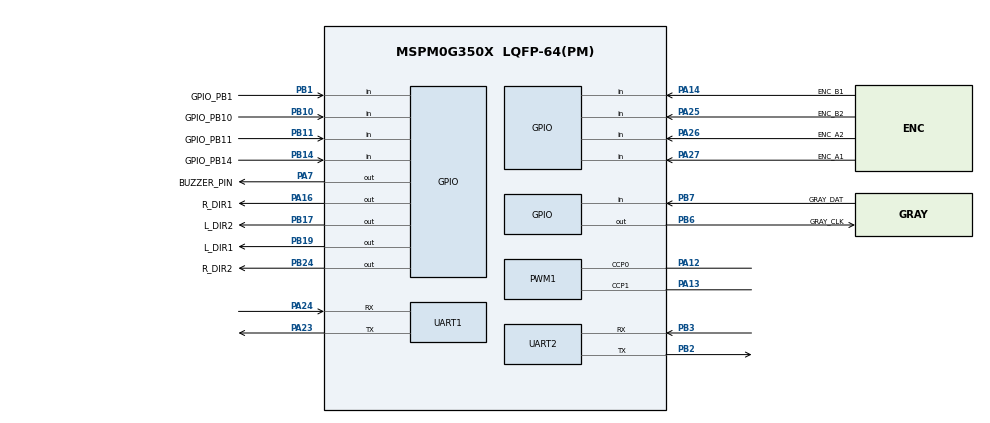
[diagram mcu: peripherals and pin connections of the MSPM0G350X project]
/**
 *
 * @cliArgs --device "MSPM0G350X" --part "Default" --package "LQFP-64(PM)" --product "mspm0_sdk@2.10.00.04"
 * @versions {"tool":"1.28.0+4696"}
 */

/**
 * Import the modules used in this configuration.
 */
const ADC12  = scripting.addModule("/ti/driverlib/ADC12", {}, false);
const ADC121 = ADC12.addInstance();
const GPIO   = scripting.addModule("/ti/driverlib/GPIO", {}, false);
const GPIO1  = GPIO.addInstance();
const GPIO2  = GPIO.addInstance();
const GPIO3  = GPIO.addInstance();
const GPIO4  = GPIO.addInstance();
const GPIO5  = GPIO.addInstance();
const GPIO6  = GPIO.addInstance();
const PWM    = scripting.addModule("/ti/driverlib/PWM", {}, false);
const PWM1   = PWM.addInstance();
const SYSCTL = scripting.addModule("/ti/driverlib/SYSCTL");
const TIMER  = scripting.addModule("/ti/driverlib/TIMER", {}, false);
const TIMER1 = TIMER.addInstance();
const UART   = scripting.addModule("/ti/driverlib/UART", {}, false);
const UART1  = UART.addInstance();
const UART2  = UART.addInstance();
const UART3  = UART.addInstance();

/**
 * Write custom configuration values to the imported modules.
 */
ADC121.$name                             = "ir_sensor";
ADC121.repeatMode                        = true;
ADC121.peripheral.adcPin0.$assign        = "PA15";
ADC121.adcPin0Config.hideOutputInversion = scripting.forceWrite(false);
ADC121.adcPin0Config.$name               = "ti_driverlib_gpio_GPIOPinGeneric8";

const Board = scripting.addModule("/ti/driverlib/Board", {}, false);

GPIO1.$name                         = "GRAY_SENSOR";
GPIO1.associatedPins.create(2);
GPIO1.associatedPins[0].$name       = "GRAY_CLK";
GPIO1.associatedPins[0].pin.$assign = "PB6";
GPIO1.associatedPins[1].$name       = "GRAY_DAT";
GPIO1.associatedPins[1].direction   = "INPUT";
GPIO1.associatedPins[1].pin.$assign = "PB7";

GPIO2.$name                         = "MOTOR_DIR";
GPIO2.associatedPins.create(4);
GPIO2.associatedPins[0].$name       = "L_DIR1";
GPIO2.associatedPins[0].pin.$assign = "PB19";
GPIO2.associatedPins[1].$name       = "L_DIR2";
GPIO2.associatedPins[1].pin.$assign = "PB17";
GPIO2.associatedPins[2].$name       = "R_DIR1";
GPIO2.associatedPins[2].pin.$assign = "PA16";
GPIO2.associatedPins[3].$name       = "R_DIR2";
GPIO2.associatedPins[3].pin.$assign = "PB24";

GPIO3.$name                         = "BUZZER";
GPIO3.associatedPins[0].$name       = "BUZZER_PIN";
GPIO3.associatedPins[0].pin.$assign = "PA7";

GPIO4.$name                         = "EXIT_ANJIAN";
GPIO4.associatedPins.create(4);
GPIO4.associatedPins[0].$name       = "GPIO_PB1";
GPIO4.associatedPins[0].direction   = "INPUT";
GPIO4.associatedPins[0].pin.$assign = "PB1";
GPIO4.associatedPins[1].$name       = "GPIO_PB10";
GPIO4.associatedPins[1].direction   = "INPUT";
GPIO4.associatedPins[1].pin.$assign = "PB10";
GPIO4.associatedPins[2].$name       = "GPIO_PB11";
GPIO4.associatedPins[2].direction   = "INPUT";
GPIO4.associatedPins[2].pin.$assign = "PB11";
GPIO4.associatedPins[3].$name       = "GPIO_PB14";
GPIO4.associatedPins[3].direction   = "INPUT";
GPIO4.associatedPins[3].pin.$assign = "PB14";

GPIO5.$name                         = "ENCODER";
GPIO5.associatedPins.create(4);
GPIO5.associatedPins[0].$name       = "ENC_A1";
GPIO5.associatedPins[0].direction   = "INPUT";
GPIO5.associatedPins[0].interruptEn = true;
GPIO5.associatedPins[0].polarity    = "RISE";
GPIO5.associatedPins[0].pin.$assign = "PA27";
GPIO5.associatedPins[1].$name       = "ENC_A2";
GPIO5.associatedPins[1].direction   = "INPUT";
GPIO5.associatedPins[1].interruptEn = true;
GPIO5.associatedPins[1].polarity    = "RISE";
GPIO5.associatedPins[1].pin.$assign = "PA26";
GPIO5.associatedPins[2].$name       = "ENC_B1";
GPIO5.associatedPins[2].direction   = "INPUT";
GPIO5.associatedPins[2].interruptEn = true;
GPIO5.associatedPins[2].polarity    = "RISE";
GPIO5.associatedPins[2].pin.$assign = "PA14";
GPIO5.associatedPins[3].$name       = "ENC_B2";
GPIO5.associatedPins[3].direction   = "INPUT";
GPIO5.associatedPins[3].interruptEn = true;
GPIO5.associatedPins[3].polarity    = "RISE";
GPIO5.associatedPins[3].pin.$assign = "PA25";

GPIO6.$name                   = "GPIO_GRP_0";
GPIO6.associatedPins[0].$name = "PIN_0";

PWM1.$name                              = "PWM_MOTOR";
PWM1.timerStartTimer                    = true;
PWM1.timerCount                         = 4000;
PWM1.pwmMode                            = "EDGE_ALIGN_UP";
PWM1.peripheral.$assign                 = "TIMG0";
PWM1.peripheral.ccp0Pin.$assign         = "PA12";
PWM1.peripheral.ccp1Pin.$assign         = "PA13";
PWM1.PWM_CHANNEL_0.$name                = "ti_driverlib_pwm_PWMTimerCC0";
PWM1.PWM_CHANNEL_0.ccValue              = 2000;
PWM1.PWM_CHANNEL_1.$name                = "ti_driverlib_pwm_PWMTimerCC1";
PWM1.PWM_CHANNEL_1.ccValue              = 2000;
PWM1.ccp0PinConfig.direction            = scripting.forceWrite("OUTPUT");
PWM1.ccp0PinConfig.hideOutputInversion  = scripting.forceWrite(false);
PWM1.ccp0PinConfig.onlyInternalResistor = scripting.forceWrite(false);
PWM1.ccp0PinConfig.passedPeripheralType = scripting.forceWrite("Digital");
PWM1.ccp0PinConfig.$name                = "ti_driverlib_gpio_GPIOPinGeneric6";
PWM1.ccp1PinConfig.direction            = scripting.forceWrite("OUTPUT");
PWM1.ccp1PinConfig.hideOutputInversion  = scripting.forceWrite(false);
PWM1.ccp1PinConfig.onlyInternalResistor = scripting.forceWrite(false);
PWM1.ccp1PinConfig.passedPeripheralType = scripting.forceWrite("Digital");
PWM1.ccp1PinConfig.$name                = "ti_driverlib_gpio_GPIOPinGeneric7";

SYSCTL.forceDefaultClkConfig = true;
SYSCTL.clockTreeEn           = true;

TIMER1.$name              = "CTRL_TIMER";
TIMER1.timerMode          = "PERIODIC_UP";
TIMER1.timerClkPrescale   = 256;
TIMER1.timerPeriod        = "5ms";
TIMER1.timerStartTimer    = true;
TIMER1.interrupts         = ["LOAD"];
TIMER1.peripheral.$assign = "TIMG6";

UART1.$name                            = "UART_CONSOLE";
UART1.targetBaudRate                   = 115200;
UART1.peripheral.$assign               = "UART2";
UART1.peripheral.rxPin.$assign         = "PA24";
UART1.peripheral.txPin.$assign         = "PA23";
UART1.txPinConfig.direction            = scripting.forceWrite("OUTPUT");
UART1.txPinConfig.hideOutputInversion  = scripting.forceWrite(false);
UART1.txPinConfig.onlyInternalResistor = scripting.forceWrite(false);
UART1.txPinConfig.passedPeripheralType = scripting.forceWrite("Digital");
UART1.txPinConfig.$name                = "ti_driverlib_gpio_GPIOPinGeneric0";
UART1.rxPinConfig.hideOutputInversion  = scripting.forceWrite(false);
UART1.rxPinConfig.onlyInternalResistor = scripting.forceWrite(false);
UART1.rxPinConfig.passedPeripheralType = scripting.forceWrite("Digital");
UART1.rxPinConfig.$name                = "ti_driverlib_gpio_GPIOPinGeneric1";

UART2.$name                            = "UART_PB";
UART2.targetBaudRate                   = 38400;
UART2.peripheral.$assign               = "UART3";
UART2.peripheral.rxPin.$assign         = "PB3";
UART2.peripheral.txPin.$assign         = "PB2";
UART2.txPinConfig.direction            = scripting.forceWrite("OUTPUT");
UART2.txPinConfig.hideOutputInversion  = scripting.forceWrite(false);
UART2.txPinConfig.onlyInternalResistor = scripting.forceWrite(false);
UART2.txPinConfig.passedPeripheralType = scripting.forceWrite("Digital");
UART2.txPinConfig.$name                = "ti_driverlib_gpio_GPIOPinGeneric10";
UART2.rxPinConfig.hideOutputInversion  = scripting.forceWrite(false);
UART2.rxPinConfig.onlyInternalResistor = scripting.forceWrite(false);
UART2.rxPinConfig.passedPeripheralType = scripting.forceWrite("Digital");
UART2.rxPinConfig.$name                = "ti_driverlib_gpio_GPIOPinGeneric11";

UART3.$name                            = "JY61P_UART";
UART3.txPinConfig.direction            = scripting.forceWrite("OUTPUT");
UART3.txPinConfig.hideOutputInversion  = scripting.forceWrite(false);
UART3.txPinConfig.onlyInternalResistor = scripting.forceWrite(false);
UART3.txPinConfig.passedPeripheralType = scripting.forceWrite("Digital");
UART3.txPinConfig.$name                = "ti_driverlib_gpio_GPIOPinGeneric2";
UART3.rxPinConfig.hideOutputInversion  = scripting.forceWrite(false);
UART3.rxPinConfig.onlyInternalResistor = scripting.forceWrite(false);
UART3.rxPinConfig.passedPeripheralType = scripting.forceWrite("Digital");
UART3.rxPinConfig.$name                = "ti_driverlib_gpio_GPIOPinGeneric3";

/**
 * Pinmux solution for unlocked pins/peripherals. This ensures that minor changes to the automatic solver in a future
 * version of the tool will not impact the pinmux you originally saw.  These lines can be completely deleted in order to
 * re-solve from scratch.
 */
ADC121.peripheral.$suggestSolution           = "ADC1";
Board.peripheral.$suggestSolution            = "DEBUGSS";
Board.peripheral.swclkPin.$suggestSolution   = "PA20";
Board.peripheral.swdioPin.$suggestSolution   = "PA19";
GPIO6.associatedPins[0].pin.$suggestSolution = "PB13";
UART3.peripheral.$suggestSolution            = "UART0";
UART3.peripheral.rxPin.$suggestSolution      = "PA1";
UART3.peripheral.txPin.$suggestSolution      = "PA0";
